# AUX_TIMER register map
Vendor: Texas Instruments
Peripheral module from a debugger description file (folder CC26x0R2F).
Registers are 32-bit, access per field, reset 0x0 unless marked. A register's access mark holds for its fields unless they carry their own. Offsets are as the file gives them; lines under a group give offsets from that group; [hi:lo] are bit positions; {n}, {i} and the like mark numbered series; 'fields as' and 'values as' point back to an identical list; <NAME> marks a mode.

## AUX_TIMER
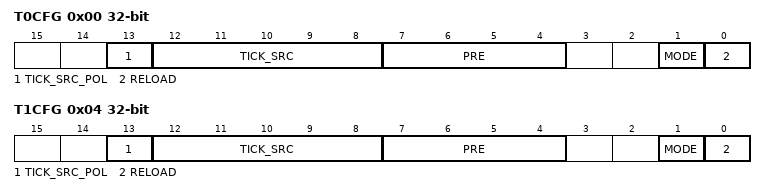
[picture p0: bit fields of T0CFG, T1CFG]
0x00 T0CFG — Timer 0 Configuration
  [13] TICK_SRC_POL rw — Tick source polarity for Timer 0.
    1=FALL (Count on falling edges of TICK_SRC.); 0=RISE (Count on rising edges of TICK_SRC.)
  [12:8] TICK_SRC rw — Select Timer 0 tick source from the synchronous event bus.
    31=ADC_IRQ (AUX_EVCTL:EVSTAT1.ADC_IRQ); 30=MCU_EVENT (AUX_EVCTL:EVSTAT1.MCU_EV); 29=ACLK_REF (AUX_EVCTL:EVSTAT1.ACLK_REF); {v}=AUXIO{v-13} (AUX_EVCTL:EVSTAT1.AUXIO{v-13}) (v=16..28); 15=AUXIO2 (AUX_EVCTL:EVSTAT0.AUXIO2); 14=AUXIO1 (AUX_EVCTL:EVSTAT0.AUXIO1); 13=AUXIO0 (AUX_EVCTL:EVSTAT0.AUXIO0); 12=AON_PROG_WU (AUX_EVCTL:EVSTAT0.AON_PROG_WU); 11=AON_SW (AUX_EVCTL:EVSTAT0.AON_SW); 10=OBSMUX1 (AUX_EVCTL:EVSTAT0.OBSMUX1); 9=OBSMUX0 (AUX_EVCTL:EVSTAT0.OBSMUX0); 8=RTC_4KHZ (AON_RTC:SUBSEC.VALUE bit 19. AON_RTC:CTL.RTC_4KHZ_EN enables this event.); 7=ADC_DONE (AUX_EVCTL:EVSTAT0.ADC_DONE); 6=SMPH_AUTOTAKE_DONE (AUX_EVCTL:EVSTAT0.SMPH_AUTOTAKE_DONE); 5=TIMER1_EV (AUX_EVCTL:EVSTAT0.TIMER1_EV); 3=TDC_DONE (AUX_EVCTL:EVSTAT0.TDC_DONE); 2=AUX_COMPB (AUX_EVCTL:EVSTAT0.AUX_COMPB); 1=AUX_COMPA (AUX_EVCTL:EVSTAT0.AUX_COMPA); 0=RTC_CH2_EV (AUX_EVCTL:EVSTAT0.AON_RTC_CH2)
  [7:4] PRE rw — Prescaler division ratio is 2^PRE: 0x0: Divide by 1. 0x1: Divide by 2. 0x2: Divide by 4. ... 0xF: Divide by 32,768.
  [1] MODE rw — Timer 0 mode. Configure source for Timer 0 prescaler.
    1=TICK (Use event set by TICK_SRC as source for prescaler.); 0=CLK (Use AUX clock as source for prescaler.)
  [0] RELOAD rw — Timer 0 reload mode.
    1=CONT (Continuous mode. Timer 0 restarts when the counter value becomes equal to or greater than ( T0TARGET.VALUE - 1).); 0=MAN (Manual mode. Timer 0 stops and T0CTL.EN becomes 0 when the counter value becomes equal to or greater than T0TARGET.VALUE.)
0x04 T1CFG — Timer 1 Configuration
  [13] TICK_SRC_POL rw — Tick source polarity for Timer 1.
    values as T0CFG.TICK_SRC_POL
  [12:8] TICK_SRC rw — Select Timer 1 tick source from the synchronous event bus.
    31=ADC_IRQ (AUX_EVCTL:EVSTAT1.ADC_IRQ); 30=MCU_EVENT (AUX_EVCTL:EVSTAT1.MCU_EV); 29=ACLK_REF (AUX_EVCTL:EVSTAT1.ACLK_REF); {v}=AUXIO{v-13} (AUX_EVCTL:EVSTAT1.AUXIO{v-13}) (v=16..28); 15=AUXIO2 (AUX_EVCTL:EVSTAT0.AUXIO2); 14=AUXIO1 (AUX_EVCTL:EVSTAT0.AUXIO1); 13=AUXIO0 (AUX_EVCTL:EVSTAT0.AUXIO0); 12=AON_PROG_WU (AUX_EVCTL:EVSTAT0.AON_PROG_WU); 11=AON_SW (AUX_EVCTL:EVSTAT0.AON_SW); 10=OBSMUX1 (AUX_EVCTL:EVSTAT0.OBSMUX1); 9=OBSMUX0 (AUX_EVCTL:EVSTAT0.OBSMUX0); 8=RTC_4KHZ (AON_RTC:SUBSEC.VALUE bit 19. AON_RTC:CTL.RTC_4KHZ_EN enables this event.); 7=ADC_DONE (AUX_EVCTL:EVSTAT0.ADC_DONE); 6=SMPH_AUTOTAKE_DONE (AUX_EVCTL:EVSTAT0.SMPH_AUTOTAKE_DONE); 4=TIMER0_EV (AUX_EVCTL:EVSTAT0.TIMER0_EV); 3=TDC_DONE (AUX_EVCTL:EVSTAT0.TDC_DONE); 2=AUX_COMPB (AUX_EVCTL:EVSTAT0.AUX_COMPB); 1=AUX_COMPA (AUX_EVCTL:EVSTAT0.AUX_COMPA); 0=RTC_CH2_EV (AUX_EVCTL:EVSTAT0.AON_RTC_CH2)
  [7:4] PRE rw — Prescaler division ratio is 2^PRE: 0x0: Divide by 1. 0x1: Divide by 2. 0x2: Divide by 4. ... 0xF: Divide by 32,768.
  [1] MODE rw — Timer 1 mode. Configure source for Timer 1 prescaler.
    values as T0CFG.MODE
  [0] RELOAD rw — Timer 1 reload mode.
    1=CONT (Continuous mode. Timer 1 restarts when the counter value becomes equal to or greater than ( T1TARGET.VALUE - 1).); 0=MAN (Manual mode. Timer 1 stops and T1CTL.EN becomes 0 when the counter value becomes equal to or greater than T1TARGET.VALUE.)
0x08 T0CTL — Timer 0 Control
  [0] EN rw — Timer 0 enable. 0: Disable Timer 0. 1: Enable Timer 0. The counter restarts from 0 when you enable Timer 0.
0x0C T0TARGET — Timer 0 Target
  [15:0] VALUE rw — Timer 0 target value. Manual Reload Mode: - Timer 0 increments until the counter value becomes equal to or greater than VALUE. - AUX_TIMER0_EV pulses high for 1 AUX clock period when the counter value is equal to or greater than VALUE. Note: When VALUE is 0, Timer 0 counts to 1. AUX_TIMER0_EV pulses high for 1 AUX clock period. Continuous Reload Mode: - Timer 0 increments until the counter value becomes equal to or greater than ( VALUE - 1), then restarts from 0. - AUX_TIMER0_EV pulses high for 1 AUX clock period when the counter value is 0, except for when you enable the timer. Note: When VALUE is less than 2, Timer 0 counter value remains 0. AUX_TIMER0_EV goes high and remains high 1 AUX clock period after you enable the timer. It is allowed to update the VALUE while the timer runs.
0x10 T1TARGET — Timer 1 Target Timer 1 counter target value
  [7:0] VALUE rw — Timer 1 target value. Manual Reload Mode: - Timer 1 increments until the counter value becomes equal to or greater than VALUE. - AUX_TIMER1_EV pulses high for 1 AUX clock period when the counter value is equal to or greater than VALUE. Note: When VALUE is 0, Timer 1 counts to 1. AUX_TIMER1_EV pulses high for 1 AUX clock period. Continuous Reload Mode: - Timer 1 increments until the counter value becomes equal to or greater than ( VALUE - 1), then restarts from 0. - AUX_TIMER1_EV pulses high for 1 AUX clock period when the counter value is 0, except for when you enable the timer. Note: When VALUE is less than 2, Timer 1 counter value remains 0. AUX_TIMER1_EV goes high and remains high 1 AUX clock period after you enable the timer. It is allowed to update the VALUE while the timer runs.
0x14 T1CTL — Timer 1 Control
  [0] EN rw — Timer 1 enable. 0: Disable Timer 1. 1: Enable Timer 1. The counter restarts from 0 when you enable Timer 1.
